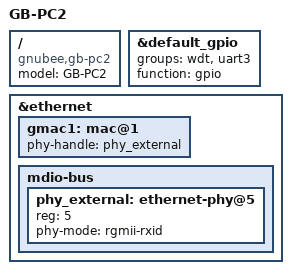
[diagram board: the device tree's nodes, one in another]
/dts-v1/;

#include "gbpc1.dts"

/ {
	compatible = "gnubee,gb-pc2", "mediatek,mt7621-soc";
	model = "GB-PC2";
};

&default_gpio {
	groups = "wdt", "uart3";
	function = "gpio";
};

&ethernet {
	gmac1: mac@1 {
		status = "ok";
		phy-handle = <&phy_external>;
	};

	mdio-bus {
		phy_external: ethernet-phy@5 {
			reg = <5>;
			phy-mode = "rgmii-rxid";
		};
	};
};
